# netx90_app register map
File version: 1.0
CPU: CM4 r0p1, little endian, MPU, FPU, 4 interrupt priority bits, 78 interrupts
Registers are 32-bit, read-write, reset 0x0 unless marked. A register's access mark holds for its fields unless they carry their own. Offsets are from the block's base; [hi:lo] are bit positions; 'fields as' and 'values as' point back to an identical list.

## mtgy (part 1 of 2)
Base 0xFF082000
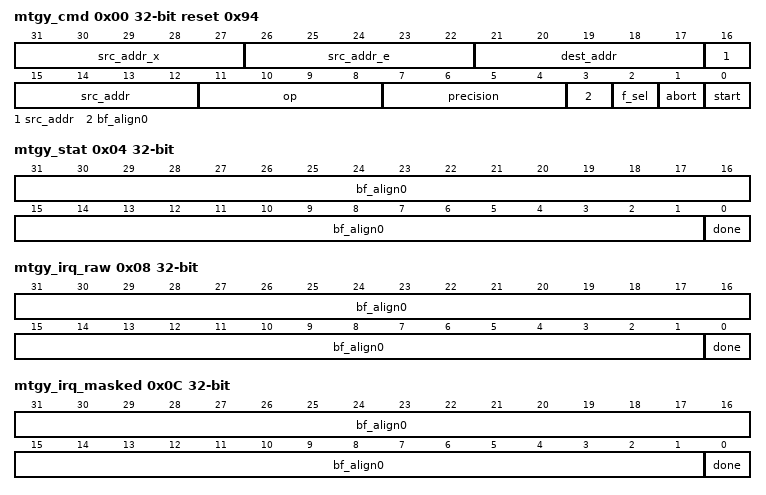
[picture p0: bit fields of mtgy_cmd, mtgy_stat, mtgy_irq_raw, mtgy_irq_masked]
0x00 mtgy_cmd reset 0x94 (reset mask 0xFFFFFFF7) — MWMM command register:
  [31:27] src_addr_x — Source address X specification. The source address X specification will be interpreted as vertical RAM location source address offset of auxiliary operand E.
  [26:22] src_addr_e — Source Address E specification. The source address E specification will be interpreted as vertical RAM location source address offset of exponent E.
  [21:17] dest_addr — Destination Address / Source Address A specification. Depending on the operation the destination address specification will be interpreted as horizontal or vertical RAM location offset or as vertical RAM location source address offset of operand A.
  [16:12] src_addr — Source Address specification. Depending on the operation the source address specification will be interpreted as horizontal or vertical RAM location offset.
  [11:8] op — The operation code of the core. Following operations codes are supported: 0: MontMult (Montgomery Multiplication Step) 1: MontR (Montgomery Parameter R) 2: MontR2 (Montgomery Parameter R2 ) 3: MontExp (Montgomery Exponentiation Step) 4: ModAdd (Modular Addition) 5: ModSub (Modular Subtraction) 6: CopyH2V (Copy from horizontal to vertical RAM location) 7: CopyV2V (Copy from vertical to vertical RAM location) 8: CopyH2H (Copy from horizontal to horizontal RAM location) 9: CopyV2H (Copy from vertical to horizontal RAM location) 10: MontMult1 (Montgomery Multiplication Step with '1' as A Operand)
  [7:4] precision — Precision of executed operations. 0: 192 bit 1: 224 bit 2: 256 bit 3: 320 bit 4: 384 bit 5: 512 bit 6: 768 bit 7: 1024 bit 8: 1536 bit 9: 2048 bit 10: 3072 bit 11: 4096 bit 15 - 12: reserved
  [3] bf_align0 — bitField alignment value for aeabi compatibility
  [2] f_sel — Finite Field Selection signal. Defines if the calculations will be performed in 1: GF(p) or 0: GF(2^m).
  [1] abort — Abort Signal of the MWMM Core. A running calculation can be aborted by issuing this signal. After writing '1', this bit will automatically be reset.
  [0] start — Start Signal of the MWMM Core. Setting this signal will instruct the Core to start the operation given by 'op' with precision specified by 'precision'. Depending on the operation the core will use the RAM location specified by 'src_addr', 'dest_addr', 'src_addr_e' and 'src_addr_x'. Calculations will be performed in the underlying finite field specified by 'f_sel'. After writing '1', this bit will automatically be reset.
0x04 mtgy_stat ro (reset mask 0x1) — MWMM status register:
  [31:1] bf_align0 — bitField alignment value for aeabi compatibility
  [0] done — Done signal from the MWMM core.
0x08 mtgy_irq_raw (reset mask 0x1) — MWMM raw IRQ: Read access shows status of unmasked IRQs. IRQs are set automatically and reset by writing to this register: Write access with '1' resets the appropriate IRQ. Write access with '0' does not influence this bit.
  [31:1] bf_align0 — bitField alignment value for aeabi compatibility
  [0] done — Done signal from the MWMM core. Only a posedge on this signal will set the interrupt.
0x0C mtgy_irq_masked ro (reset mask 0x1) — MWMM masked IRQ: Shows status of masked IRQs.
  fields as mtgy_stat
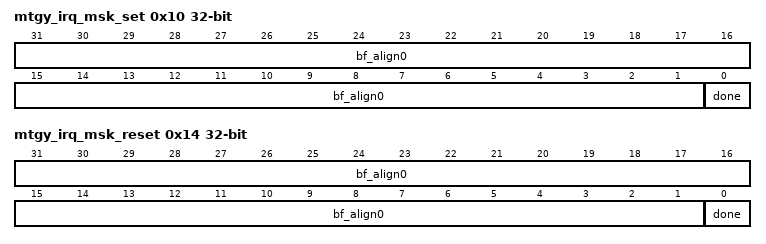
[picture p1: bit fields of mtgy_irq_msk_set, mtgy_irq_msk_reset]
0x10 mtgy_irq_msk_set (reset mask 0x1) — MWMM IRQ mask set: The IRQ mask enables interrupt requests for corresponding interrupt sources. As its bits might be changed by different software tasks, the IRQ mask register is not writable directly, but by set and reset masks: Write access with '1' sets interrupt mask bit. Write access with '0' does not influence this bit. Read access shows actual interrupt mask. Attention: Before activating interrupt mask, delete old pending interrupts by writing the same value to mtgy_irq_raw.
  fields as mtgy_stat
0x14 mtgy_irq_msk_reset (reset mask 0x1) — MWMM IRQ mask reset: This is the corresponding reset mask to disable interrupt requests for corresponding interrupt sources: Write access with '1' resets interrupt mask bit. Write access with '0' does not influence this bit. Read access shows actual interrupt mask.
  fields as mtgy_stat
0x1000 mtgy_op_tc0 — MWMM TC register 0
  [31:0] val — data bits 31..0
0x1004 mtgy_op_tc1 — MWMM TC register 1
  [31:0] val — data bits 63..32
0x1008 mtgy_op_tc2 — MWMM TC register 2
  [31:0] val — data bits 95..64
0x100C mtgy_op_tc3 — MWMM TC register 3
  [31:0] val — data bits 127..96
0x1010 mtgy_op_tc4 — MWMM TC register 4
  [31:0] val — data bits 159..128
0x1014 mtgy_op_tc5 — MWMM TC register 5
  [31:0] val — data bits 191..160
0x1018 mtgy_op_tc6 — MWMM TC register 6
  [31:0] val — data bits 223..192
0x101C mtgy_op_tc7 — MWMM TC register 7
  [31:0] val — data bits 255..224
0x1020 mtgy_op_tc8 — MWMM TC register 8
  [31:0] val — data bits 287..256
0x1024 mtgy_op_tc9 — MWMM TC register 9
  [31:0] val — data bits 319..288
0x1028 mtgy_op_tc10 — MWMM TC register 10
  [31:0] val — data bits 351..320
0x102C mtgy_op_tc11 — MWMM TC register 11
  [31:0] val — data bits 383..352
0x1030 mtgy_op_tc12 — MWMM TC register 12
  [31:0] val — data bits 415..384
0x1034 mtgy_op_tc13 — MWMM TC register 13
  [31:0] val — data bits 447..416
0x1038 mtgy_op_tc14 — MWMM TC register 14
  [31:0] val — data bits 479..448
0x103C mtgy_op_tc15 — MWMM TC register 15
  [31:0] val — data bits 511..480
0x1040 mtgy_op_tc16 — MWMM TC register 16
  [31:0] val — data bits 543..512
0x1044 mtgy_op_tc17 — MWMM TC register 17
  [31:0] val — data bits 575..544
0x1048 mtgy_op_tc18 — MWMM TC register 18
  [31:0] val — data bits 607..576
0x104C mtgy_op_tc19 — MWMM TC register 19
  [31:0] val — data bits 639..608
0x1050 mtgy_op_tc20 — MWMM TC register 20
  [31:0] val — data bits 671..640
0x1054 mtgy_op_tc21 — MWMM TC register 21
  [31:0] val — data bits 703..672
0x1058 mtgy_op_tc22 — MWMM TC register 22
  [31:0] val — data bits 735..704
0x105C mtgy_op_tc23 — MWMM TC register 23
  [31:0] val — data bits 767..736
0x1060 mtgy_op_tc24 — MWMM TC register 24
  [31:0] val — data bits 799..768
0x1064 mtgy_op_tc25 — MWMM TC register 25
  [31:0] val — data bits 831..800
0x1068 mtgy_op_tc26 — MWMM TC register 26
  [31:0] val — data bits 863..832
0x106C mtgy_op_tc27 — MWMM TC register 27
  [31:0] val — data bits 895..864
0x1070 mtgy_op_tc28 — MWMM TC register 28
  [31:0] val — data bits 927..896
0x1074 mtgy_op_tc29 — MWMM TC register 29
  [31:0] val — data bits 959..928
0x1078 mtgy_op_tc30 — MWMM TC register 30
  [31:0] val — data bits 991..960
0x107C mtgy_op_tc31 — MWMM TC register 31
  [31:0] val — data bits 1023..992
0x1080 mtgy_op_tc32 — MWMM TC register 32
  [31:0] val — data bits 1055..1024
0x1084 mtgy_op_tc33 — MWMM TC register 33
  [31:0] val — data bits 1087..1056
0x1088 mtgy_op_tc34 — MWMM TC register 34
  [31:0] val — data bits 1119..1088
0x108C mtgy_op_tc35 — MWMM TC register 35
  [31:0] val — data bits 1151..1120
0x1090 mtgy_op_tc36 — MWMM TC register 36
  [31:0] val — data bits 1183..1152
0x1094 mtgy_op_tc37 — MWMM TC register 37
  [31:0] val — data bits 1215..1184
0x1098 mtgy_op_tc38 — MWMM TC register 38
  [31:0] val — data bits 1247..1216
0x109C mtgy_op_tc39 — MWMM TC register 39
  [31:0] val — data bits 1279..1248
0x10A0 mtgy_op_tc40 — MWMM TC register 40
  [31:0] val — data bits 1311..1280
0x10A4 mtgy_op_tc41 — MWMM TC register 41
  [31:0] val — data bits 1343..1312
0x10A8 mtgy_op_tc42 — MWMM TC register 42
  [31:0] val — data bits 1375..1344
0x10AC mtgy_op_tc43 — MWMM TC register 43
  [31:0] val — data bits 1407..1376
0x10B0 mtgy_op_tc44 — MWMM TC register 44
  [31:0] val — data bits 1439..1408
0x10B4 mtgy_op_tc45 — MWMM TC register 45
  [31:0] val — data bits 1471..1440
0x10B8 mtgy_op_tc46 — MWMM TC register 46
  [31:0] val — data bits 1503..1472
0x10BC mtgy_op_tc47 — MWMM TC register 47
  [31:0] val — data bits 1535..1504
0x10C0 mtgy_op_tc48 — MWMM TC register 48
  [31:0] val — data bits 1567..1536
0x10C4 mtgy_op_tc49 — MWMM TC register 49
  [31:0] val — data bits 1599..1568
0x10C8 mtgy_op_tc50 — MWMM TC register 50
  [31:0] val — data bits 1631..1600
0x10CC mtgy_op_tc51 — MWMM TC register 51
  [31:0] val — data bits 1663..1632
0x10D0 mtgy_op_tc52 — MWMM TC register 52
  [31:0] val — data bits 1695..1664
0x10D4 mtgy_op_tc53 — MWMM TC register 53
  [31:0] val — data bits 1727..1696
0x10D8 mtgy_op_tc54 — MWMM TC register 54
  [31:0] val — data bits 1759..1728
0x10DC mtgy_op_tc55 — MWMM TC register 55
  [31:0] val — data bits 1791..1760
0x10E0 mtgy_op_tc56 — MWMM TC register 56
  [31:0] val — data bits 1823..1792
0x10E4 mtgy_op_tc57 — MWMM TC register 57
  [31:0] val — data bits 1855..1824
0x10E8 mtgy_op_tc58 — MWMM TC register 58
  [31:0] val — data bits 1887..1856
0x10EC mtgy_op_tc59 — MWMM TC register 59
  [31:0] val — data bits 1919..1888
0x10F0 mtgy_op_tc60 — MWMM TC register 60
  [31:0] val — data bits 1951..1920
0x10F4 mtgy_op_tc61 — MWMM TC register 61
  [31:0] val — data bits 1983..1952
0x10F8 mtgy_op_tc62 — MWMM TC register 62
  [31:0] val — data bits 2015..1984
0x10FC mtgy_op_tc63 — MWMM TC register 63
  [31:0] val — data bits 2047..2016
0x1100 mtgy_op_tc64 — MWMM TC register 64
  [31:0] val — data bits 2079..2048
0x1104 mtgy_op_tc65 — MWMM TC register 65
  [31:0] val — data bits 2111..2080
0x1108 mtgy_op_tc66 — MWMM TC register 66
  [31:0] val — data bits 2143..2112
0x110C mtgy_op_tc67 — MWMM TC register 67
  [31:0] val — data bits 2175..2144
0x1110 mtgy_op_tc68 — MWMM TC register 68
  [31:0] val — data bits 2207..2176
0x1114 mtgy_op_tc69 — MWMM TC register 69
  [31:0] val — data bits 2239..2208
0x1118 mtgy_op_tc70 — MWMM TC register 70
  [31:0] val — data bits 2271..2240
0x111C mtgy_op_tc71 — MWMM TC register 71
  [31:0] val — data bits 2303..2272
0x1120 mtgy_op_tc72 — MWMM TC register 72
  [31:0] val — data bits 2335..2304
0x1124 mtgy_op_tc73 — MWMM TC register 73
  [31:0] val — data bits 2367..2336
0x1128 mtgy_op_tc74 — MWMM TC register 74
  [31:0] val — data bits 2399..2368
0x112C mtgy_op_tc75 — MWMM TC register 75
  [31:0] val — data bits 2431..2400
0x1130 mtgy_op_tc76 — MWMM TC register 76
  [31:0] val — data bits 2463..2432
0x1134 mtgy_op_tc77 — MWMM TC register 77
  [31:0] val — data bits 2495..2464
0x1138 mtgy_op_tc78 — MWMM TC register 78
  [31:0] val — data bits 2527..2496
0x113C mtgy_op_tc79 — MWMM TC register 79
  [31:0] val — data bits 2559..2528
0x1140 mtgy_op_tc80 — MWMM TC register 80
  [31:0] val — data bits 2591..2560
0x1144 mtgy_op_tc81 — MWMM TC register 81
  [31:0] val — data bits 2623..2592
0x1148 mtgy_op_tc82 — MWMM TC register 82
  [31:0] val — data bits 2655..2624
0x114C mtgy_op_tc83 — MWMM TC register 83
  [31:0] val — data bits 2687..2656
0x1150 mtgy_op_tc84 — MWMM TC register 84
  [31:0] val — data bits 2719..2688
0x1154 mtgy_op_tc85 — MWMM TC register 85
  [31:0] val — data bits 2751..2720
0x1158 mtgy_op_tc86 — MWMM TC register 86
  [31:0] val — data bits 2783..2752
0x115C mtgy_op_tc87 — MWMM TC register 87
  [31:0] val — data bits 2815..2784
0x1160 mtgy_op_tc88 — MWMM TC register 88
  [31:0] val — data bits 2847..2816
0x1164 mtgy_op_tc89 — MWMM TC register 89
  [31:0] val — data bits 2879..2848
0x1168 mtgy_op_tc90 — MWMM TC register 90
  [31:0] val — data bits 2911..2880
0x116C mtgy_op_tc91 — MWMM TC register 91
  [31:0] val — data bits 2943..2912
0x1170 mtgy_op_tc92 — MWMM TC register 92
  [31:0] val — data bits 2975..2944
0x1174 mtgy_op_tc93 — MWMM TC register 93
  [31:0] val — data bits 3007..2976
0x1178 mtgy_op_tc94 — MWMM TC register 94
  [31:0] val — data bits 3039..3008
0x117C mtgy_op_tc95 — MWMM TC register 95
  [31:0] val — data bits 3071..3040
0x1180 mtgy_op_tc96 — MWMM TC register 96
  [31:0] val — data bits 3103..3072
0x1184 mtgy_op_tc97 — MWMM TC register 97
  [31:0] val — data bits 3135..3104
0x1188 mtgy_op_tc98 — MWMM TC register 98
  [31:0] val — data bits 3167..3136
0x118C mtgy_op_tc99 — MWMM TC register 99
  [31:0] val — data bits 3199..3168
0x1190 mtgy_op_tc100 — MWMM TC register 100
  [31:0] val — data bits 3231..3200
0x1194 mtgy_op_tc101 — MWMM TC register 101
  [31:0] val — data bits 3263..3232
0x1198 mtgy_op_tc102 — MWMM TC register 102
  [31:0] val — data bits 3295..3264
0x119C mtgy_op_tc103 — MWMM TC register 103
  [31:0] val — data bits 3327..3296
0x11A0 mtgy_op_tc104 — MWMM TC register 104
  [31:0] val — data bits 3359..3328
0x11A4 mtgy_op_tc105 — MWMM TC register 105
  [31:0] val — data bits 3391..3360
0x11A8 mtgy_op_tc106 — MWMM TC register 106
  [31:0] val — data bits 3423..3392
0x11AC mtgy_op_tc107 — MWMM TC register 107
  [31:0] val — data bits 3455..3424
0x11B0 mtgy_op_tc108 — MWMM TC register 108
  [31:0] val — data bits 3487..3456
0x11B4 mtgy_op_tc109 — MWMM TC register 109
  [31:0] val — data bits 3519..3488
0x11B8 mtgy_op_tc110 — MWMM TC register 110
  [31:0] val — data bits 3551..3520
0x11BC mtgy_op_tc111 — MWMM TC register 111
  [31:0] val — data bits 3583..3552
0x11C0 mtgy_op_tc112 — MWMM TC register 112
  [31:0] val — data bits 3615..3584
0x11C4 mtgy_op_tc113 — MWMM TC register 113
  [31:0] val — data bits 3647..3616
0x11C8 mtgy_op_tc114 — MWMM TC register 114
  [31:0] val — data bits 3679..3648
0x11CC mtgy_op_tc115 — MWMM TC register 115
  [31:0] val — data bits 3711..3680
0x11D0 mtgy_op_tc116 — MWMM TC register 116
  [31:0] val — data bits 3743..3712
0x11D4 mtgy_op_tc117 — MWMM TC register 117
  [31:0] val — data bits 3775..3744
0x11D8 mtgy_op_tc118 — MWMM TC register 118
  [31:0] val — data bits 3807..3776
0x11DC mtgy_op_tc119 — MWMM TC register 119
  [31:0] val — data bits 3839..3808
0x11E0 mtgy_op_tc120 — MWMM TC register 120
  [31:0] val — data bits 3871..3840
0x11E4 mtgy_op_tc121 — MWMM TC register 121
  [31:0] val — data bits 3903..3872
0x11E8 mtgy_op_tc122 — MWMM TC register 122
  [31:0] val — data bits 3935..3904
0x11EC mtgy_op_tc123 — MWMM TC register 123
  [31:0] val — data bits 3967..3936
0x11F0 mtgy_op_tc124 — MWMM TC register 124
  [31:0] val — data bits 3999..3968
0x11F4 mtgy_op_tc125 — MWMM TC register 125
  [31:0] val — data bits 4031..4000
0x11F8 mtgy_op_tc126 — MWMM TC register 126
  [31:0] val — data bits 4063..4032
0x11FC mtgy_op_tc127 — MWMM TC register 127
  [31:0] val — data bits 4095..4064
0x1200 mtgy_op_ts0 — MWMM TS register 0
  [31:0] val — data bits 31..0
0x1204 mtgy_op_ts1 — MWMM TS register 1
  [31:0] val — data bits 63..32
0x1208 mtgy_op_ts2 — MWMM TS register 2
  [31:0] val — data bits 95..64
0x120C mtgy_op_ts3 — MWMM TS register 3
  [31:0] val — data bits 127..96
0x1210 mtgy_op_ts4 — MWMM TS register 4
  [31:0] val — data bits 159..128
0x1214 mtgy_op_ts5 — MWMM TS register 5
  [31:0] val — data bits 191..160
0x1218 mtgy_op_ts6 — MWMM TS register 6
  [31:0] val — data bits 223..192
0x121C mtgy_op_ts7 — MWMM TS register 7
  [31:0] val — data bits 255..224
0x1220 mtgy_op_ts8 — MWMM TS register 8
  [31:0] val — data bits 287..256
0x1224 mtgy_op_ts9 — MWMM TS register 9
  [31:0] val — data bits 319..288
0x1228 mtgy_op_ts10 — MWMM TS register 10
  [31:0] val — data bits 351..320
0x122C mtgy_op_ts11 — MWMM TS register 11
  [31:0] val — data bits 383..352
0x1230 mtgy_op_ts12 — MWMM TS register 12
  [31:0] val — data bits 415..384
0x1234 mtgy_op_ts13 — MWMM TS register 13
  [31:0] val — data bits 447..416
0x1238 mtgy_op_ts14 — MWMM TS register 14
  [31:0] val — data bits 479..448
0x123C mtgy_op_ts15 — MWMM TS register 15
  [31:0] val — data bits 511..480
0x1240 mtgy_op_ts16 — MWMM TS register 16
  [31:0] val — data bits 543..512
0x1244 mtgy_op_ts17 — MWMM TS register 17
  [31:0] val — data bits 575..544
0x1248 mtgy_op_ts18 — MWMM TS register 18
  [31:0] val — data bits 607..576
0x124C mtgy_op_ts19 — MWMM TS register 19
  [31:0] val — data bits 639..608
0x1250 mtgy_op_ts20 — MWMM TS register 20
  [31:0] val — data bits 671..640
0x1254 mtgy_op_ts21 — MWMM TS register 21
  [31:0] val — data bits 703..672
0x1258 mtgy_op_ts22 — MWMM TS register 22
  [31:0] val — data bits 735..704
0x125C mtgy_op_ts23 — MWMM TS register 23
  [31:0] val — data bits 767..736
0x1260 mtgy_op_ts24 — MWMM TS register 24
  [31:0] val — data bits 799..768
0x1264 mtgy_op_ts25 — MWMM TS register 25
  [31:0] val — data bits 831..800
0x1268 mtgy_op_ts26 — MWMM TS register 26
  [31:0] val — data bits 863..832
0x126C mtgy_op_ts27 — MWMM TS register 27
  [31:0] val — data bits 895..864
0x1270 mtgy_op_ts28 — MWMM TS register 28
  [31:0] val — data bits 927..896
0x1274 mtgy_op_ts29 — MWMM TS register 29
  [31:0] val — data bits 959..928
0x1278 mtgy_op_ts30 — MWMM TS register 30
  [31:0] val — data bits 991..960
0x127C mtgy_op_ts31 — MWMM TS register 31
  [31:0] val — data bits 1023..992
0x1280 mtgy_op_ts32 — MWMM TS register 32
  [31:0] val — data bits 1055..1024
0x1284 mtgy_op_ts33 — MWMM TS register 33
  [31:0] val — data bits 1087..1056
0x1288 mtgy_op_ts34 — MWMM TS register 34
  [31:0] val — data bits 1119..1088
0x128C mtgy_op_ts35 — MWMM TS register 35
  [31:0] val — data bits 1151..1120
0x1290 mtgy_op_ts36 — MWMM TS register 36
  [31:0] val — data bits 1183..1152
0x1294 mtgy_op_ts37 — MWMM TS register 37
  [31:0] val — data bits 1215..1184
0x1298 mtgy_op_ts38 — MWMM TS register 38
  [31:0] val — data bits 1247..1216
0x129C mtgy_op_ts39 — MWMM TS register 39
  [31:0] val — data bits 1279..1248
0x12A0 mtgy_op_ts40 — MWMM TS register 40
  [31:0] val — data bits 1311..1280
0x12A4 mtgy_op_ts41 — MWMM TS register 41
  [31:0] val — data bits 1343..1312
0x12A8 mtgy_op_ts42 — MWMM TS register 42
  [31:0] val — data bits 1375..1344
0x12AC mtgy_op_ts43 — MWMM TS register 43
  [31:0] val — data bits 1407..1376
0x12B0 mtgy_op_ts44 — MWMM TS register 44
  [31:0] val — data bits 1439..1408
0x12B4 mtgy_op_ts45 — MWMM TS register 45
  [31:0] val — data bits 1471..1440
0x12B8 mtgy_op_ts46 — MWMM TS register 46
  [31:0] val — data bits 1503..1472
0x12BC mtgy_op_ts47 — MWMM TS register 47
  [31:0] val — data bits 1535..1504
0x12C0 mtgy_op_ts48 — MWMM TS register 48
  [31:0] val — data bits 1567..1536
0x12C4 mtgy_op_ts49 — MWMM TS register 49
  [31:0] val — data bits 1599..1568
0x12C8 mtgy_op_ts50 — MWMM TS register 50
  [31:0] val — data bits 1631..1600
0x12CC mtgy_op_ts51 — MWMM TS register 51
  [31:0] val — data bits 1663..1632
0x12D0 mtgy_op_ts52 — MWMM TS register 52
  [31:0] val — data bits 1695..1664
0x12D4 mtgy_op_ts53 — MWMM TS register 53
  [31:0] val — data bits 1727..1696
0x12D8 mtgy_op_ts54 — MWMM TS register 54
  [31:0] val — data bits 1759..1728
0x12DC mtgy_op_ts55 — MWMM TS register 55
  [31:0] val — data bits 1791..1760
0x12E0 mtgy_op_ts56 — MWMM TS register 56
  [31:0] val — data bits 1823..1792
0x12E4 mtgy_op_ts57 — MWMM TS register 57
  [31:0] val — data bits 1855..1824
0x12E8 mtgy_op_ts58 — MWMM TS register 58
  [31:0] val — data bits 1887..1856
0x12EC mtgy_op_ts59 — MWMM TS register 59
  [31:0] val — data bits 1919..1888
0x12F0 mtgy_op_ts60 — MWMM TS register 60
  [31:0] val — data bits 1951..1920
0x12F4 mtgy_op_ts61 — MWMM TS register 61
  [31:0] val — data bits 1983..1952
0x12F8 mtgy_op_ts62 — MWMM TS register 62
  [31:0] val — data bits 2015..1984
0x12FC mtgy_op_ts63 — MWMM TS register 63
  [31:0] val — data bits 2047..2016
0x1300 mtgy_op_ts64 — MWMM TS register 64
  [31:0] val — data bits 2079..2048
0x1304 mtgy_op_ts65 — MWMM TS register 65
  [31:0] val — data bits 2111..2080
0x1308 mtgy_op_ts66 — MWMM TS register 66
  [31:0] val — data bits 2143..2112
0x130C mtgy_op_ts67 — MWMM TS register 67
  [31:0] val — data bits 2175..2144
0x1310 mtgy_op_ts68 — MWMM TS register 68
  [31:0] val — data bits 2207..2176
0x1314 mtgy_op_ts69 — MWMM TS register 69
  [31:0] val — data bits 2239..2208
0x1318 mtgy_op_ts70 — MWMM TS register 70
  [31:0] val — data bits 2271..2240
0x131C mtgy_op_ts71 — MWMM TS register 71
  [31:0] val — data bits 2303..2272
0x1320 mtgy_op_ts72 — MWMM TS register 72
  [31:0] val — data bits 2335..2304
0x1324 mtgy_op_ts73 — MWMM TS register 73
  [31:0] val — data bits 2367..2336
0x1328 mtgy_op_ts74 — MWMM TS register 74
  [31:0] val — data bits 2399..2368
0x132C mtgy_op_ts75 — MWMM TS register 75
  [31:0] val — data bits 2431..2400
0x1330 mtgy_op_ts76 — MWMM TS register 76
  [31:0] val — data bits 2463..2432
0x1334 mtgy_op_ts77 — MWMM TS register 77
  [31:0] val — data bits 2495..2464
0x1338 mtgy_op_ts78 — MWMM TS register 78
  [31:0] val — data bits 2527..2496
0x133C mtgy_op_ts79 — MWMM TS register 79
  [31:0] val — data bits 2559..2528
0x1340 mtgy_op_ts80 — MWMM TS register 80
  [31:0] val — data bits 2591..2560
0x1344 mtgy_op_ts81 — MWMM TS register 81
  [31:0] val — data bits 2623..2592
0x1348 mtgy_op_ts82 — MWMM TS register 82
  [31:0] val — data bits 2655..2624
0x134C mtgy_op_ts83 — MWMM TS register 83
  [31:0] val — data bits 2687..2656
0x1350 mtgy_op_ts84 — MWMM TS register 84
  [31:0] val — data bits 2719..2688
0x1354 mtgy_op_ts85 — MWMM TS register 85
  [31:0] val — data bits 2751..2720
0x1358 mtgy_op_ts86 — MWMM TS register 86
  [31:0] val — data bits 2783..2752
0x135C mtgy_op_ts87 — MWMM TS register 87
  [31:0] val — data bits 2815..2784
0x1360 mtgy_op_ts88 — MWMM TS register 88
  [31:0] val — data bits 2847..2816
0x1364 mtgy_op_ts89 — MWMM TS register 89
  [31:0] val — data bits 2879..2848
0x1368 mtgy_op_ts90 — MWMM TS register 90
  [31:0] val — data bits 2911..2880
0x136C mtgy_op_ts91 — MWMM TS register 91
  [31:0] val — data bits 2943..2912
0x1370 mtgy_op_ts92 — MWMM TS register 92
  [31:0] val — data bits 2975..2944
0x1374 mtgy_op_ts93 — MWMM TS register 93
  [31:0] val — data bits 3007..2976
0x1378 mtgy_op_ts94 — MWMM TS register 94
  [31:0] val — data bits 3039..3008
0x137C mtgy_op_ts95 — MWMM TS register 95
  [31:0] val — data bits 3071..3040
0x1380 mtgy_op_ts96 — MWMM TS register 96
  [31:0] val — data bits 3103..3072
0x1384 mtgy_op_ts97 — MWMM TS register 97
  [31:0] val — data bits 3135..3104
0x1388 mtgy_op_ts98 — MWMM TS register 98
  [31:0] val — data bits 3167..3136
0x138C mtgy_op_ts99 — MWMM TS register 99
  [31:0] val — data bits 3199..3168
0x1390 mtgy_op_ts100 — MWMM TS register 100
  [31:0] val — data bits 3231..3200
0x1394 mtgy_op_ts101 — MWMM TS register 101
  [31:0] val — data bits 3263..3232
0x1398 mtgy_op_ts102 — MWMM TS register 102
  [31:0] val — data bits 3295..3264
0x139C mtgy_op_ts103 — MWMM TS register 103
  [31:0] val — data bits 3327..3296
0x13A0 mtgy_op_ts104 — MWMM TS register 104
  [31:0] val — data bits 3359..3328
0x13A4 mtgy_op_ts105 — MWMM TS register 105
  [31:0] val — data bits 3391..3360
0x13A8 mtgy_op_ts106 — MWMM TS register 106
  [31:0] val — data bits 3423..3392
0x13AC mtgy_op_ts107 — MWMM TS register 107
  [31:0] val — data bits 3455..3424
0x13B0 mtgy_op_ts108 — MWMM TS register 108
  [31:0] val — data bits 3487..3456
0x13B4 mtgy_op_ts109 — MWMM TS register 109
  [31:0] val — data bits 3519..3488
0x13B8 mtgy_op_ts110 — MWMM TS register 110
  [31:0] val — data bits 3551..3520
0x13BC mtgy_op_ts111 — MWMM TS register 111
  [31:0] val — data bits 3583..3552
0x13C0 mtgy_op_ts112 — MWMM TS register 112
  [31:0] val — data bits 3615..3584
0x13C4 mtgy_op_ts113 — MWMM TS register 113
  [31:0] val — data bits 3647..3616
0x13C8 mtgy_op_ts114 — MWMM TS register 114
  [31:0] val — data bits 3679..3648
0x13CC mtgy_op_ts115 — MWMM TS register 115
  [31:0] val — data bits 3711..3680
0x13D0 mtgy_op_ts116 — MWMM TS register 116
  [31:0] val — data bits 3743..3712
0x13D4 mtgy_op_ts117 — MWMM TS register 117
  [31:0] val — data bits 3775..3744
0x13D8 mtgy_op_ts118 — MWMM TS register 118
  [31:0] val — data bits 3807..3776
0x13DC mtgy_op_ts119 — MWMM TS register 119
  [31:0] val — data bits 3839..3808
0x13E0 mtgy_op_ts120 — MWMM TS register 120
  [31:0] val — data bits 3871..3840
0x13E4 mtgy_op_ts121 — MWMM TS register 121
  [31:0] val — data bits 3903..3872
0x13E8 mtgy_op_ts122 — MWMM TS register 122
  [31:0] val — data bits 3935..3904
0x13EC mtgy_op_ts123 — MWMM TS register 123
  [31:0] val — data bits 3967..3936
0x13F0 mtgy_op_ts124 — MWMM TS register 124
  [31:0] val — data bits 3999..3968
0x13F4 mtgy_op_ts125 — MWMM TS register 125
  [31:0] val — data bits 4031..4000
0x13F8 mtgy_op_ts126 — MWMM TS register 126
  [31:0] val — data bits 4063..4032
0x13FC mtgy_op_ts127 — MWMM TS register 127
  [31:0] val — data bits 4095..4064
0x1400 mtgy_op_p0 — MWMM operand P register 0
  [31:0] val — data bits 31..0
0x1404 mtgy_op_p1 — MWMM operand P register 1
  [31:0] val — data bits 63..32
0x1408 mtgy_op_p2 — MWMM operand P register 2
  [31:0] val — data bits 95..64
0x140C mtgy_op_p3 — MWMM operand P register 3
  [31:0] val — data bits 127..96
0x1410 mtgy_op_p4 — MWMM operand P register 4
  [31:0] val — data bits 159..128
0x1414 mtgy_op_p5 — MWMM operand P register 5
  [31:0] val — data bits 191..160
0x1418 mtgy_op_p6 — MWMM operand P register 6
  [31:0] val — data bits 223..192
0x141C mtgy_op_p7 — MWMM operand P register 7
  [31:0] val — data bits 255..224
0x1420 mtgy_op_p8 — MWMM operand P register 8
  [31:0] val — data bits 287..256
0x1424 mtgy_op_p9 — MWMM operand P register 9
  [31:0] val — data bits 319..288
0x1428 mtgy_op_p10 — MWMM operand P register 10
  [31:0] val — data bits 351..320
0x142C mtgy_op_p11 — MWMM operand P register 11
  [31:0] val — data bits 383..352
0x1430 mtgy_op_p12 — MWMM operand P register 12
  [31:0] val — data bits 415..384
0x1434 mtgy_op_p13 — MWMM operand P register 13
  [31:0] val — data bits 447..416
0x1438 mtgy_op_p14 — MWMM operand P register 14
  [31:0] val — data bits 479..448
0x143C mtgy_op_p15 — MWMM operand P register 15
  [31:0] val — data bits 511..480
0x1440 mtgy_op_p16 — MWMM operand P register 16
  [31:0] val — data bits 543..512
0x1444 mtgy_op_p17 — MWMM operand P register 17
  [31:0] val — data bits 575..544
0x1448 mtgy_op_p18 — MWMM operand P register 18
  [31:0] val — data bits 607..576
0x144C mtgy_op_p19 — MWMM operand P register 19
  [31:0] val — data bits 639..608
0x1450 mtgy_op_p20 — MWMM operand P register 20
  [31:0] val — data bits 671..640
0x1454 mtgy_op_p21 — MWMM operand P register 21
  [31:0] val — data bits 703..672
0x1458 mtgy_op_p22 — MWMM operand P register 22
  [31:0] val — data bits 735..704
0x145C mtgy_op_p23 — MWMM operand P register 23
  [31:0] val — data bits 767..736
0x1460 mtgy_op_p24 — MWMM operand P register 24
  [31:0] val — data bits 799..768
0x1464 mtgy_op_p25 — MWMM operand P register 25
  [31:0] val — data bits 831..800
0x1468 mtgy_op_p26 — MWMM operand P register 26
  [31:0] val — data bits 863..832
0x146C mtgy_op_p27 — MWMM operand P register 27
  [31:0] val — data bits 895..864
0x1470 mtgy_op_p28 — MWMM operand P register 28
  [31:0] val — data bits 927..896
0x1474 mtgy_op_p29 — MWMM operand P register 29
  [31:0] val — data bits 959..928
0x1478 mtgy_op_p30 — MWMM operand P register 30
  [31:0] val — data bits 991..960
0x147C mtgy_op_p31 — MWMM operand P register 31
  [31:0] val — data bits 1023..992
0x1480 mtgy_op_p32 — MWMM operand P register 32
  [31:0] val — data bits 1055..1024
0x1484 mtgy_op_p33 — MWMM operand P register 33
  [31:0] val — data bits 1087..1056
0x1488 mtgy_op_p34 — MWMM operand P register 34
  [31:0] val — data bits 1119..1088
0x148C mtgy_op_p35 — MWMM operand P register 35
  [31:0] val — data bits 1151..1120
0x1490 mtgy_op_p36 — MWMM operand P register 36
  [31:0] val — data bits 1183..1152
0x1494 mtgy_op_p37 — MWMM operand P register 37
  [31:0] val — data bits 1215..1184
0x1498 mtgy_op_p38 — MWMM operand P register 38
  [31:0] val — data bits 1247..1216
0x149C mtgy_op_p39 — MWMM operand P register 39
  [31:0] val — data bits 1279..1248
0x14A0 mtgy_op_p40 — MWMM operand P register 40
  [31:0] val — data bits 1311..1280
0x14A4 mtgy_op_p41 — MWMM operand P register 41
  [31:0] val — data bits 1343..1312
0x14A8 mtgy_op_p42 — MWMM operand P register 42
  [31:0] val — data bits 1375..1344
0x14AC mtgy_op_p43 — MWMM operand P register 43
  [31:0] val — data bits 1407..1376
0x14B0 mtgy_op_p44 — MWMM operand P register 44
  [31:0] val — data bits 1439..1408
0x14B4 mtgy_op_p45 — MWMM operand P register 45
  [31:0] val — data bits 1471..1440
0x14B8 mtgy_op_p46 — MWMM operand P register 46
  [31:0] val — data bits 1503..1472
0x14BC mtgy_op_p47 — MWMM operand P register 47
  [31:0] val — data bits 1535..1504
0x14C0 mtgy_op_p48 — MWMM operand P register 48
  [31:0] val — data bits 1567..1536
0x14C4 mtgy_op_p49 — MWMM operand P register 49
  [31:0] val — data bits 1599..1568
0x14C8 mtgy_op_p50 — MWMM operand P register 50
  [31:0] val — data bits 1631..1600
0x14CC mtgy_op_p51 — MWMM operand P register 51
  [31:0] val — data bits 1663..1632
0x14D0 mtgy_op_p52 — MWMM operand P register 52
  [31:0] val — data bits 1695..1664
0x14D4 mtgy_op_p53 — MWMM operand P register 53
  [31:0] val — data bits 1727..1696
0x14D8 mtgy_op_p54 — MWMM operand P register 54
  [31:0] val — data bits 1759..1728
0x14DC mtgy_op_p55 — MWMM operand P register 55
  [31:0] val — data bits 1791..1760
0x14E0 mtgy_op_p56 — MWMM operand P register 56
  [31:0] val — data bits 1823..1792
0x14E4 mtgy_op_p57 — MWMM operand P register 57
  [31:0] val — data bits 1855..1824
0x14E8 mtgy_op_p58 — MWMM operand P register 58
  [31:0] val — data bits 1887..1856
0x14EC mtgy_op_p59 — MWMM operand P register 59
  [31:0] val — data bits 1919..1888
0x14F0 mtgy_op_p60 — MWMM operand P register 60
  [31:0] val — data bits 1951..1920
0x14F4 mtgy_op_p61 — MWMM operand P register 61
  [31:0] val — data bits 1983..1952
0x14F8 mtgy_op_p62 — MWMM operand P register 62
  [31:0] val — data bits 2015..1984
0x14FC mtgy_op_p63 — MWMM operand P register 63
  [31:0] val — data bits 2047..2016
0x1500 mtgy_op_p64 — MWMM operand P register 64
  [31:0] val — data bits 2079..2048
0x1504 mtgy_op_p65 — MWMM operand P register 65
  [31:0] val — data bits 2111..2080
0x1508 mtgy_op_p66 — MWMM operand P register 66
  [31:0] val — data bits 2143..2112
0x150C mtgy_op_p67 — MWMM operand P register 67
  [31:0] val — data bits 2175..2144
0x1510 mtgy_op_p68 — MWMM operand P register 68
  [31:0] val — data bits 2207..2176
0x1514 mtgy_op_p69 — MWMM operand P register 69
  [31:0] val — data bits 2239..2208
0x1518 mtgy_op_p70 — MWMM operand P register 70
  [31:0] val — data bits 2271..2240
0x151C mtgy_op_p71 — MWMM operand P register 71
  [31:0] val — data bits 2303..2272
0x1520 mtgy_op_p72 — MWMM operand P register 72
  [31:0] val — data bits 2335..2304
0x1524 mtgy_op_p73 — MWMM operand P register 73
  [31:0] val — data bits 2367..2336
0x1528 mtgy_op_p74 — MWMM operand P register 74
  [31:0] val — data bits 2399..2368
0x152C mtgy_op_p75 — MWMM operand P register 75
  [31:0] val — data bits 2431..2400
0x1530 mtgy_op_p76 — MWMM operand P register 76
  [31:0] val — data bits 2463..2432
0x1534 mtgy_op_p77 — MWMM operand P register 77
  [31:0] val — data bits 2495..2464
0x1538 mtgy_op_p78 — MWMM operand P register 78
  [31:0] val — data bits 2527..2496
0x153C mtgy_op_p79 — MWMM operand P register 79
  [31:0] val — data bits 2559..2528
0x1540 mtgy_op_p80 — MWMM operand P register 80
  [31:0] val — data bits 2591..2560
0x1544 mtgy_op_p81 — MWMM operand P register 81
  [31:0] val — data bits 2623..2592
0x1548 mtgy_op_p82 — MWMM operand P register 82
  [31:0] val — data bits 2655..2624
0x154C mtgy_op_p83 — MWMM operand P register 83
  [31:0] val — data bits 2687..2656
0x1550 mtgy_op_p84 — MWMM operand P register 84
  [31:0] val — data bits 2719..2688
0x1554 mtgy_op_p85 — MWMM operand P register 85
  [31:0] val — data bits 2751..2720
0x1558 mtgy_op_p86 — MWMM operand P register 86
  [31:0] val — data bits 2783..2752
0x155C mtgy_op_p87 — MWMM operand P register 87
  [31:0] val — data bits 2815..2784
0x1560 mtgy_op_p88 — MWMM operand P register 88
  [31:0] val — data bits 2847..2816
0x1564 mtgy_op_p89 — MWMM operand P register 89
  [31:0] val — data bits 2879..2848
0x1568 mtgy_op_p90 — MWMM operand P register 90
  [31:0] val — data bits 2911..2880
0x156C mtgy_op_p91 — MWMM operand P register 91
  [31:0] val — data bits 2943..2912
0x1570 mtgy_op_p92 — MWMM operand P register 92
  [31:0] val — data bits 2975..2944
0x1574 mtgy_op_p93 — MWMM operand P register 93
  [31:0] val — data bits 3007..2976
0x1578 mtgy_op_p94 — MWMM operand P register 94
  [31:0] val — data bits 3039..3008
0x157C mtgy_op_p95 — MWMM operand P register 95
  [31:0] val — data bits 3071..3040
0x1580 mtgy_op_p96 — MWMM operand P register 96
  [31:0] val — data bits 3103..3072
0x1584 mtgy_op_p97 — MWMM operand P register 97
  [31:0] val — data bits 3135..3104
0x1588 mtgy_op_p98 — MWMM operand P register 98
  [31:0] val — data bits 3167..3136
0x158C mtgy_op_p99 — MWMM operand P register 99
  [31:0] val — data bits 3199..3168
0x1590 mtgy_op_p100 — MWMM operand P register 100
  [31:0] val — data bits 3231..3200
0x1594 mtgy_op_p101 — MWMM operand P register 101
  [31:0] val — data bits 3263..3232
0x1598 mtgy_op_p102 — MWMM operand P register 102
  [31:0] val — data bits 3295..3264
0x159C mtgy_op_p103 — MWMM operand P register 103
  [31:0] val — data bits 3327..3296
0x15A0 mtgy_op_p104 — MWMM operand P register 104
  [31:0] val — data bits 3359..3328
0x15A4 mtgy_op_p105 — MWMM operand P register 105
  [31:0] val — data bits 3391..3360
0x15A8 mtgy_op_p106 — MWMM operand P register 106
  [31:0] val — data bits 3423..3392
0x15AC mtgy_op_p107 — MWMM operand P register 107
  [31:0] val — data bits 3455..3424
0x15B0 mtgy_op_p108 — MWMM operand P register 108
  [31:0] val — data bits 3487..3456
0x15B4 mtgy_op_p109 — MWMM operand P register 109
  [31:0] val — data bits 3519..3488
0x15B8 mtgy_op_p110 — MWMM operand P register 110
  [31:0] val — data bits 3551..3520
0x15BC mtgy_op_p111 — MWMM operand P register 111
  [31:0] val — data bits 3583..3552
0x15C0 mtgy_op_p112 — MWMM operand P register 112
  [31:0] val — data bits 3615..3584
0x15C4 mtgy_op_p113 — MWMM operand P register 113
  [31:0] val — data bits 3647..3616
0x15C8 mtgy_op_p114 — MWMM operand P register 114
  [31:0] val — data bits 3679..3648
0x15CC mtgy_op_p115 — MWMM operand P register 115
  [31:0] val — data bits 3711..3680
0x15D0 mtgy_op_p116 — MWMM operand P register 116
  [31:0] val — data bits 3743..3712
0x15D4 mtgy_op_p117 — MWMM operand P register 117
  [31:0] val — data bits 3775..3744
0x15D8 mtgy_op_p118 — MWMM operand P register 118
  [31:0] val — data bits 3807..3776
0x15DC mtgy_op_p119 — MWMM operand P register 119
  [31:0] val — data bits 3839..3808
0x15E0 mtgy_op_p120 — MWMM operand P register 120
  [31:0] val — data bits 3871..3840
0x15E4 mtgy_op_p121 — MWMM operand P register 121
  [31:0] val — data bits 3903..3872
0x15E8 mtgy_op_p122 — MWMM operand P register 122
  [31:0] val — data bits 3935..3904
0x15EC mtgy_op_p123 — MWMM operand P register 123
  [31:0] val — data bits 3967..3936
0x15F0 mtgy_op_p124 — MWMM operand P register 124
  [31:0] val — data bits 3999..3968
0x15F4 mtgy_op_p125 — MWMM operand P register 125
  [31:0] val — data bits 4031..4000
0x15F8 mtgy_op_p126 — MWMM operand P register 126
  [31:0] val — data bits 4063..4032
0x15FC mtgy_op_p127 — MWMM operand P register 127
  [31:0] val — data bits 4095..4064
0x1600 mtgy_op_b0 — MWMM operand B register 0
  [31:0] val — data bits 31..0
0x1604 mtgy_op_b1 — MWMM operand B register 1
  [31:0] val — data bits 63..32
0x1608 mtgy_op_b2 — MWMM operand B register 2
  [31:0] val — data bits 95..64
0x160C mtgy_op_b3 — MWMM operand B register 3
  [31:0] val — data bits 127..96
0x1610 mtgy_op_b4 — MWMM operand B register 4
  [31:0] val — data bits 159..128
0x1614 mtgy_op_b5 — MWMM operand B register 5
  [31:0] val — data bits 191..160
0x1618 mtgy_op_b6 — MWMM operand B register 6
  [31:0] val — data bits 223..192
0x161C mtgy_op_b7 — MWMM operand B register 7
  [31:0] val — data bits 255..224
0x1620 mtgy_op_b8 — MWMM operand B register 8
  [31:0] val — data bits 287..256
0x1624 mtgy_op_b9 — MWMM operand B register 9
  [31:0] val — data bits 319..288
0x1628 mtgy_op_b10 — MWMM operand B register 10
  [31:0] val — data bits 351..320
0x162C mtgy_op_b11 — MWMM operand B register 11
  [31:0] val — data bits 383..352
0x1630 mtgy_op_b12 — MWMM operand B register 12
  [31:0] val — data bits 415..384
0x1634 mtgy_op_b13 — MWMM operand B register 13
  [31:0] val — data bits 447..416
0x1638 mtgy_op_b14 — MWMM operand B register 14
  [31:0] val — data bits 479..448
0x163C mtgy_op_b15 — MWMM operand B register 15
  [31:0] val — data bits 511..480
0x1640 mtgy_op_b16 — MWMM operand B register 16
  [31:0] val — data bits 543..512
0x1644 mtgy_op_b17 — MWMM operand B register 17
  [31:0] val — data bits 575..544
0x1648 mtgy_op_b18 — MWMM operand B register 18
  [31:0] val — data bits 607..576
0x164C mtgy_op_b19 — MWMM operand B register 19
  [31:0] val — data bits 639..608
0x1650 mtgy_op_b20 — MWMM operand B register 20
  [31:0] val — data bits 671..640
0x1654 mtgy_op_b21 — MWMM operand B register 21
  [31:0] val — data bits 703..672
0x1658 mtgy_op_b22 — MWMM operand B register 22
  [31:0] val — data bits 735..704
0x165C mtgy_op_b23 — MWMM operand B register 23
  [31:0] val — data bits 767..736
0x1660 mtgy_op_b24 — MWMM operand B register 24
  [31:0] val — data bits 799..768
0x1664 mtgy_op_b25 — MWMM operand B register 25
  [31:0] val — data bits 831..800
0x1668 mtgy_op_b26 — MWMM operand B register 26
  [31:0] val — data bits 863..832
0x166C mtgy_op_b27 — MWMM operand B register 27
  [31:0] val — data bits 895..864
0x1670 mtgy_op_b28 — MWMM operand B register 28
  [31:0] val — data bits 927..896
0x1674 mtgy_op_b29 — MWMM operand B register 29
  [31:0] val — data bits 959..928
0x1678 mtgy_op_b30 — MWMM operand B register 30
  [31:0] val — data bits 991..960
0x167C mtgy_op_b31 — MWMM operand B register 31
  [31:0] val — data bits 1023..992
0x1680 mtgy_op_b32 — MWMM operand B register 32
  [31:0] val — data bits 1055..1024
0x1684 mtgy_op_b33 — MWMM operand B register 33
  [31:0] val — data bits 1087..1056
0x1688 mtgy_op_b34 — MWMM operand B register 34
  [31:0] val — data bits 1119..1088
0x168C mtgy_op_b35 — MWMM operand B register 35
  [31:0] val — data bits 1151..1120
0x1690 mtgy_op_b36 — MWMM operand B register 36
  [31:0] val — data bits 1183..1152
0x1694 mtgy_op_b37 — MWMM operand B register 37
  [31:0] val — data bits 1215..1184
0x1698 mtgy_op_b38 — MWMM operand B register 38
  [31:0] val — data bits 1247..1216
0x169C mtgy_op_b39 — MWMM operand B register 39
  [31:0] val — data bits 1279..1248
0x16A0 mtgy_op_b40 — MWMM operand B register 40
  [31:0] val — data bits 1311..1280
0x16A4 mtgy_op_b41 — MWMM operand B register 41
  [31:0] val — data bits 1343..1312
0x16A8 mtgy_op_b42 — MWMM operand B register 42
  [31:0] val — data bits 1375..1344
0x16AC mtgy_op_b43 — MWMM operand B register 43
  [31:0] val — data bits 1407..1376
0x16B0 mtgy_op_b44 — MWMM operand B register 44
  [31:0] val — data bits 1439..1408
0x16B4 mtgy_op_b45 — MWMM operand B register 45
  [31:0] val — data bits 1471..1440
0x16B8 mtgy_op_b46 — MWMM operand B register 46
  [31:0] val — data bits 1503..1472
0x16BC mtgy_op_b47 — MWMM operand B register 47
  [31:0] val — data bits 1535..1504
0x16C0 mtgy_op_b48 — MWMM operand B register 48
  [31:0] val — data bits 1567..1536
0x16C4 mtgy_op_b49 — MWMM operand B register 49
  [31:0] val — data bits 1599..1568
